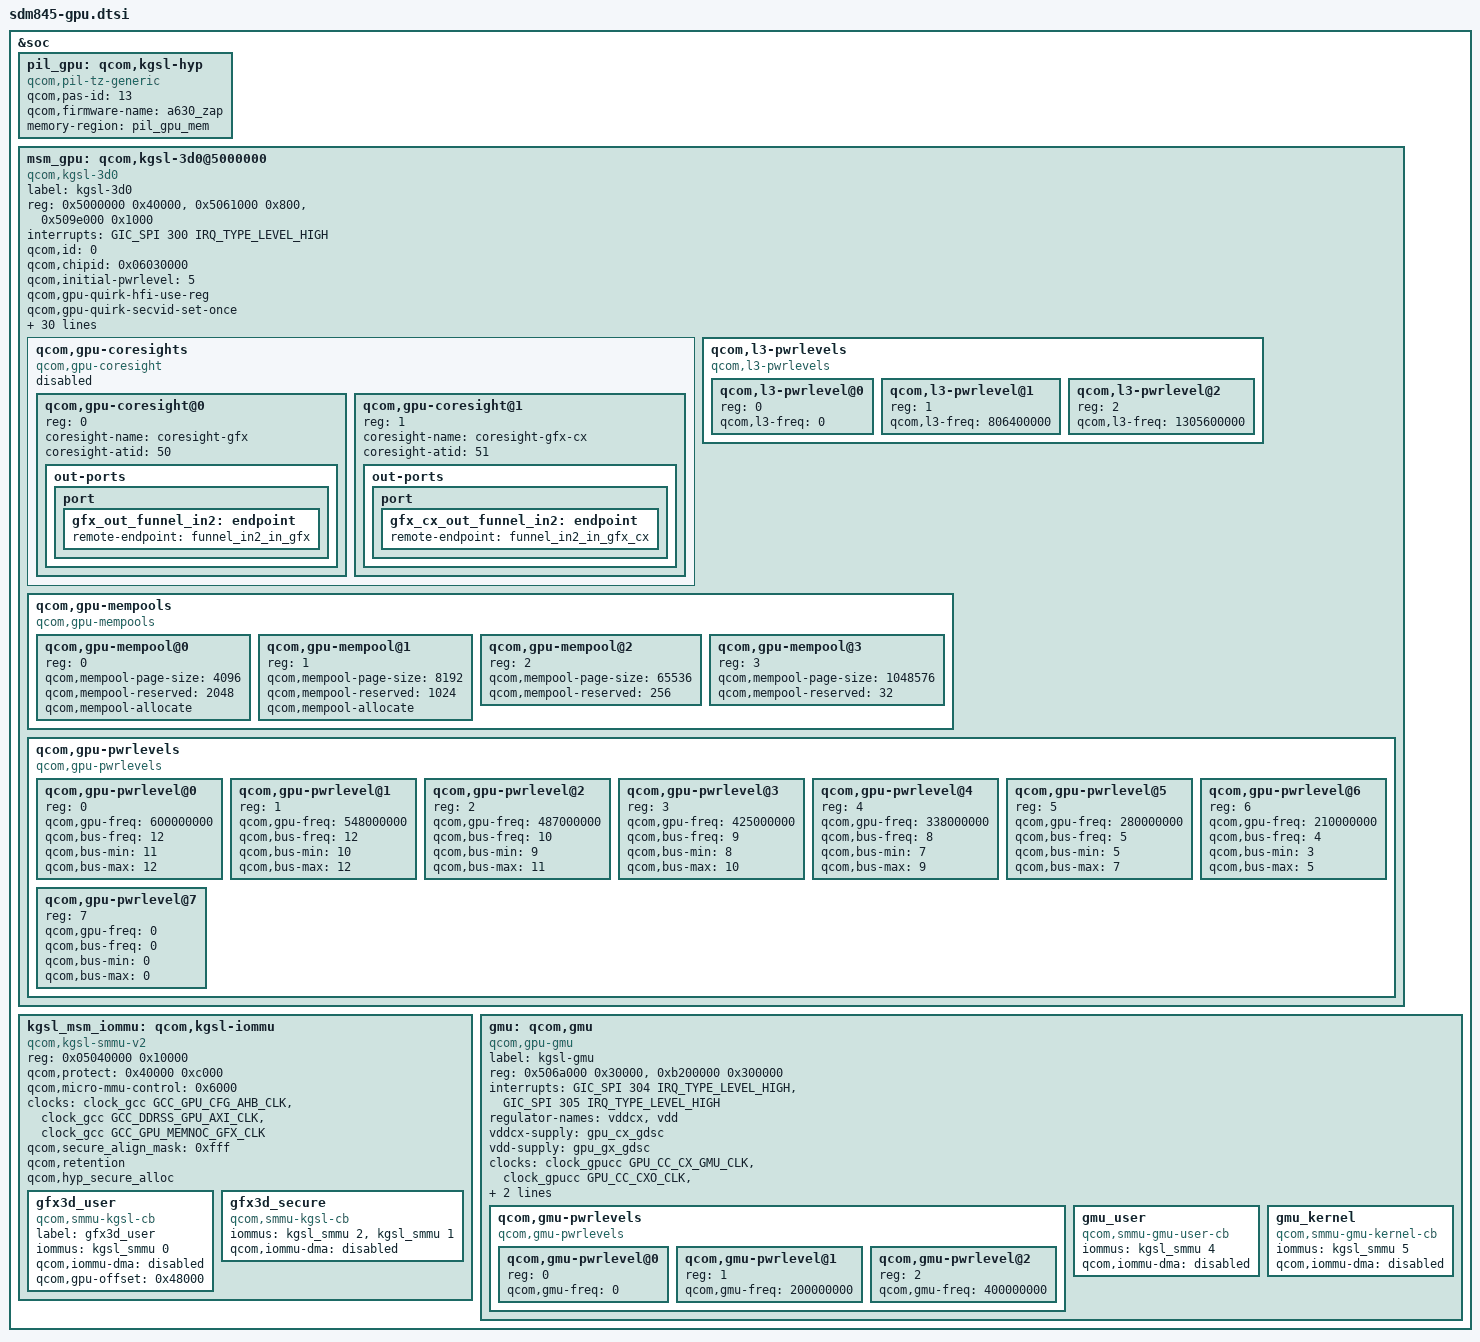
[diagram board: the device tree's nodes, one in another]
// SPDX-License-Identifier: GPL-2.0-only
/*
 * Copyright (c) 2017-2019, The Linux Foundation. All rights reserved.
 * Copyright (c) 2021-2022, 2025, Pavel Dubrova <pashadubrova@gmail.com>
 */

#define MHZ_TO_KBPS(mhz, w) ((mhz * 1000000 * w) / (1024))

&soc {
	pil_gpu: qcom,kgsl-hyp {
		compatible = "qcom,pil-tz-generic";
		qcom,pas-id = <13>;
		qcom,firmware-name = "a630_zap";
		memory-region = <&pil_gpu_mem>;
	};

	msm_gpu: qcom,kgsl-3d0@5000000 {
		label = "kgsl-3d0";
		compatible = "qcom,kgsl-3d0", "qcom,kgsl-3d";
		status = "ok";
		reg = <0x5000000 0x40000>, <0x5061000 0x800>,
			<0x509e000 0x1000>;
		reg-names = "kgsl_3d0_reg_memory", "cx_dbgc",
			"cx_misc";
		interrupts = <GIC_SPI 300 IRQ_TYPE_LEVEL_HIGH>;
		interrupt-names = "kgsl_3d0_irq";
		qcom,id = <0>;

		qcom,chipid = <0x06030000>;

		qcom,initial-pwrlevel = <5>;

		qcom,gpu-quirk-hfi-use-reg;
		qcom,gpu-quirk-secvid-set-once;

		qcom,idle-timeout = <80>; //msecs
		qcom,no-nap;

		qcom,highest-bank-bit = <15>;

		qcom,min-access-length = <32>;

		qcom,ubwc-mode = <2>;

		qcom,snapshot-size = <1048576>; //bytes

		qcom,gpu-qdss-stm = <0x161c0000 0x40000>; // base addr, size

		qcom,tsens-name = "tsens_tz_sensor12";

		tzone-names = "gpu0-usr", "gpu1-usr";

		qcom,pm-qos-active-latency = <460>;

		clocks = <&clock_gfx GPU_CC_GX_GFX3D_CLK>,
			<&clock_gpucc GPU_CC_CXO_CLK>,
			<&clock_gcc GCC_DDRSS_GPU_AXI_CLK>,
			<&clock_gcc GCC_GPU_MEMNOC_GFX_CLK>,
			<&clock_gpucc GPU_CC_CX_GMU_CLK>;

		clock-names = "core_clk", "rbbmtimer_clk", "mem_clk",
				"mem_iface_clk", "gmu_clk";

		qcom,isense-clk-on-level = <1>;

		interconnects = <&mem_noc MASTER_GRAPHICS_3D
				&mc_virt SLAVE_EBI1>;
		interconnect-names = "gpu_icc_path";

		qcom,bus-table-ddr =
				<MHZ_TO_KBPS(0, 4)>,    /* index=0  */
				<MHZ_TO_KBPS(100, 4)>,  /* index=1  */
				<MHZ_TO_KBPS(150, 4)>,  /* index=2  */
				<MHZ_TO_KBPS(200, 4)>,  /* index=3  */
				<MHZ_TO_KBPS(300, 4)>,  /* index=4  */
				<MHZ_TO_KBPS(412, 4)>,  /* index=5  */
				<MHZ_TO_KBPS(547, 4)>,  /* index=6  */
				<MHZ_TO_KBPS(681, 4)>,  /* index=7  */
				<MHZ_TO_KBPS(768, 4)>,  /* index=8  */
				<MHZ_TO_KBPS(1017, 4)>, /* index=9  */
				<MHZ_TO_KBPS(1296, 4)>, /* index=10 */
				<MHZ_TO_KBPS(1555, 4)>, /* index=11 */
				<MHZ_TO_KBPS(1804, 4)>; /* index=12 */

		qcom,bus-table-cnoc =
				<0>,   /* Off */
				<100>; /* On */

		/* GDSC regulator names */
		regulator-names = "vddcx", "vdd";
		/* GDSC oxili regulators */
		vddcx-supply = <&gpu_cx_gdsc>;
		vdd-supply = <&gpu_gx_gdsc>;

		/* GPU related llc slices */
		cache-slice-names = "gpu", "gpuhtw";

		qcom,gpu-coresights {
			#address-cells = <1>;
			#size-cells = <0>;
			compatible = "qcom,gpu-coresight";

			status = "disabled";

			qcom,gpu-coresight@0 {
				reg = <0>;
				coresight-name = "coresight-gfx";
				coresight-atid = <50>;
				out-ports {
					port {
						gfx_out_funnel_in2: endpoint {
							remote-endpoint =
							  <&funnel_in2_in_gfx>;
						};
					};
				};
			};

			qcom,gpu-coresight@1 {
				reg = <1>;
				coresight-name = "coresight-gfx-cx";
				coresight-atid = <51>;
				out-ports {
					port {
						gfx_cx_out_funnel_in2: endpoint {
							remote-endpoint =
							  <&funnel_in2_in_gfx_cx>;
						};
					};
				};
			};
		};

		qcom,l3-pwrlevels {
			#address-cells = <1>;
			#size-cells = <0>;

			compatible = "qcom,l3-pwrlevels";

			qcom,l3-pwrlevel@0 {
				reg = <0>;
				qcom,l3-freq = <0>;
			 };

			qcom,l3-pwrlevel@1 {
				reg = <1>;
				qcom,l3-freq = <806400000>;
			 };

			qcom,l3-pwrlevel@2 {
				reg = <2>;
				qcom,l3-freq = <1305600000>;
			 };
		 };

		/* GPU Mempools */
		qcom,gpu-mempools {
			#address-cells = <1>;
			#size-cells = <0>;
			compatible = "qcom,gpu-mempools";

			/* 4K Page Pool configuration */
			qcom,gpu-mempool@0 {
				reg = <0>;
				qcom,mempool-page-size = <4096>;
				qcom,mempool-reserved = <2048>;
				qcom,mempool-allocate;
			};
			/* 8K Page Pool configuration */
			qcom,gpu-mempool@1 {
				reg = <1>;
				qcom,mempool-page-size = <8192>;
				qcom,mempool-reserved = <1024>;
				qcom,mempool-allocate;
			};
			/* 64K Page Pool configuration */
			qcom,gpu-mempool@2 {
				reg = <2>;
				qcom,mempool-page-size = <65536>;
				qcom,mempool-reserved = <256>;
			};
			/* 1M Page Pool configuration */
			qcom,gpu-mempool@3 {
				reg = <3>;
				qcom,mempool-page-size = <1048576>;
				qcom,mempool-reserved = <32>;
			};
		};

		/* Power levels */
		qcom,gpu-pwrlevels {
			#address-cells = <1>;
			#size-cells = <0>;

			compatible = "qcom,gpu-pwrlevels";

			qcom,gpu-pwrlevel@0 {
				reg = <0>;
				qcom,gpu-freq = <600000000>;
				qcom,bus-freq = <12>;
				qcom,bus-min = <11>;
				qcom,bus-max = <12>;
			};


			qcom,gpu-pwrlevel@1 {
				reg = <1>;
				qcom,gpu-freq = <548000000>;
				qcom,bus-freq = <12>;
				qcom,bus-min = <10>;
				qcom,bus-max = <12>;
			};

			qcom,gpu-pwrlevel@2 {
				reg = <2>;
				qcom,gpu-freq = <487000000>;
				qcom,bus-freq = <10>;
				qcom,bus-min = <9>;
				qcom,bus-max = <11>;
			};


			qcom,gpu-pwrlevel@3 {
				reg = <3>;
				qcom,gpu-freq = <425000000>;
				qcom,bus-freq = <9>;
				qcom,bus-min = <8>;
				qcom,bus-max = <10>;
			};

			qcom,gpu-pwrlevel@4 {
				reg = <4>;
				qcom,gpu-freq = <338000000>;
				qcom,bus-freq = <8>;
				qcom,bus-min = <7>;
				qcom,bus-max = <9>;
			};


			qcom,gpu-pwrlevel@5 {
				reg = <5>;
				qcom,gpu-freq = <280000000>;
				qcom,bus-freq = <5>;
				qcom,bus-min = <5>;
				qcom,bus-max = <7>;
			};

			qcom,gpu-pwrlevel@6 {
				reg = <6>;
				qcom,gpu-freq = <210000000>;
				qcom,bus-freq = <4>;
				qcom,bus-min = <3>;
				qcom,bus-max = <5>;
			};

			qcom,gpu-pwrlevel@7 {
				reg = <7>;
				qcom,gpu-freq = <0>;
				qcom,bus-freq = <0>;
				qcom,bus-min = <0>;
				qcom,bus-max = <0>;
			};
		};

	};

	kgsl_msm_iommu: qcom,kgsl-iommu {
		compatible = "qcom,kgsl-smmu-v2";

		reg = <0x05040000 0x10000>;
		/* CB5(ATOS) & CB5/6/7 are protected by HYP */
		qcom,protect = <0x40000 0xc000>;
		qcom,micro-mmu-control = <0x6000>;

		clocks =<&clock_gcc GCC_GPU_CFG_AHB_CLK>,
			<&clock_gcc GCC_DDRSS_GPU_AXI_CLK>,
			<&clock_gcc GCC_GPU_MEMNOC_GFX_CLK>;

		clock-names = "iface_clk", "mem_clk", "mem_iface_clk";

		qcom,secure_align_mask = <0xfff>;
		qcom,retention;
		qcom,hyp_secure_alloc;

		gfx3d_user: gfx3d_user {
			compatible = "qcom,smmu-kgsl-cb";
			label = "gfx3d_user";
			iommus = <&kgsl_smmu 0>;
			qcom,iommu-dma = "disabled";
			qcom,gpu-offset = <0x48000>;
		};

		gfx3d_secure: gfx3d_secure {
			compatible = "qcom,smmu-kgsl-cb";
			iommus = <&kgsl_smmu 2>, <&kgsl_smmu 1>;
			qcom,iommu-dma = "disabled";
		};
	};

	gmu: qcom,gmu {
		label = "kgsl-gmu";
		compatible = "qcom,gpu-gmu";

		reg = <0x506a000 0x30000>, <0xb200000 0x300000>;
		reg-names = "kgsl_gmu_reg", "kgsl_gmu_pdc_reg";

		interrupts = <GIC_SPI 304 IRQ_TYPE_LEVEL_HIGH>,
			     <GIC_SPI 305 IRQ_TYPE_LEVEL_HIGH>;
		interrupt-names = "kgsl_hfi_irq", "kgsl_gmu_irq";

		regulator-names = "vddcx", "vdd";
		vddcx-supply = <&gpu_cx_gdsc>;
		vdd-supply = <&gpu_gx_gdsc>;

		clocks = <&clock_gpucc GPU_CC_CX_GMU_CLK>,
				<&clock_gpucc GPU_CC_CXO_CLK>,
				<&clock_gcc GCC_DDRSS_GPU_AXI_CLK>,
				<&clock_gcc GCC_GPU_MEMNOC_GFX_CLK>;

		clock-names = "gmu_clk", "cxo_clk", "axi_clk",
				"memnoc_clk";

		qcom,gmu-pwrlevels {
			#address-cells = <1>;
			#size-cells = <0>;

			compatible = "qcom,gmu-pwrlevels";

			/* GMU power levels must go from lowest to highest */
			qcom,gmu-pwrlevel@0 {
				reg = <0>;
				qcom,gmu-freq = <0>;
			};

			qcom,gmu-pwrlevel@1 {
				reg = <1>;
				qcom,gmu-freq = <200000000>;
			};

			qcom,gmu-pwrlevel@2 {
				reg = <2>;
				qcom,gmu-freq = <400000000>;
			};
		};

		gmu_user: gmu_user {
			compatible = "qcom,smmu-gmu-user-cb";
			iommus = <&kgsl_smmu 4>;
			qcom,iommu-dma = "disabled";
		};

		gmu_kernel: gmu_kernel {
			compatible = "qcom,smmu-gmu-kernel-cb";
			iommus = <&kgsl_smmu 5>;
			qcom,iommu-dma = "disabled";
		};
	};
};
